AUTOSAR XML (schema 4-0-3)
package /ComponentTypes
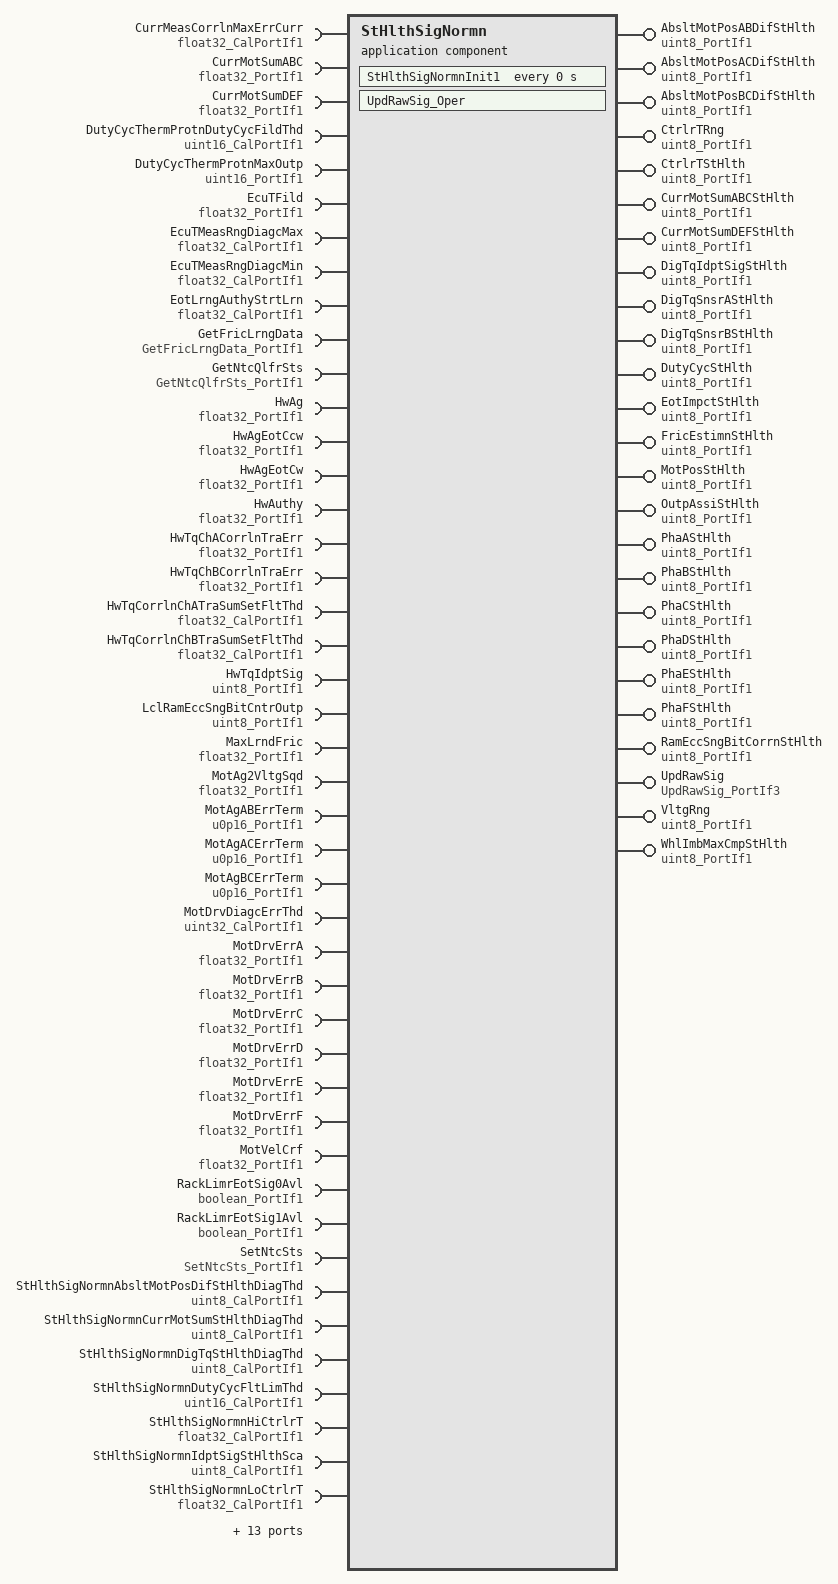
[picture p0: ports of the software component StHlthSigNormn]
  application sw component type StHlthSigNormn
    25 x provide port:
      AbsltMotPosABDifStHlth: nonqueued-sender-com-spec{data-element=Val, init-value=100}, provided-interface=uint8_PortIf1
      AbsltMotPosACDifStHlth: nonqueued-sender-com-spec{data-element=Val, init-value=100}, provided-interface=uint8_PortIf1
      AbsltMotPosBCDifStHlth: nonqueued-sender-com-spec{data-element=Val, init-value=100}, provided-interface=uint8_PortIf1
      CtrlrTRng: nonqueued-sender-com-spec{data-element=Val, init-value=0}, provided-interface=uint8_PortIf1
      CtrlrTStHlth: nonqueued-sender-com-spec{data-element=Val, init-value=100}, provided-interface=uint8_PortIf1
      CurrMotSumABCStHlth: nonqueued-sender-com-spec{data-element=Val, init-value=100}, provided-interface=uint8_PortIf1
      CurrMotSumDEFStHlth: nonqueued-sender-com-spec{data-element=Val, init-value=100}, provided-interface=uint8_PortIf1
      DigTqIdptSigStHlth: nonqueued-sender-com-spec{data-element=Val, init-value=100}, provided-interface=uint8_PortIf1
      DigTqSnsrAStHlth: nonqueued-sender-com-spec{data-element=Val, init-value=100}, provided-interface=uint8_PortIf1
      DigTqSnsrBStHlth: nonqueued-sender-com-spec{data-element=Val, init-value=100}, provided-interface=uint8_PortIf1
      DutyCycStHlth: nonqueued-sender-com-spec{data-element=Val, init-value=100}, provided-interface=uint8_PortIf1
      EotImpctStHlth: nonqueued-sender-com-spec{data-element=Val, init-value=100}, provided-interface=uint8_PortIf1
      FricEstimnStHlth: nonqueued-sender-com-spec{data-element=Val, init-value=100}, provided-interface=uint8_PortIf1
      MotPosStHlth: nonqueued-sender-com-spec{data-element=Val, init-value=100}, provided-interface=uint8_PortIf1
      OutpAssiStHlth: nonqueued-sender-com-spec{data-element=Val, init-value=100}, provided-interface=uint8_PortIf1
      PhaAStHlth: nonqueued-sender-com-spec{data-element=Val, init-value=100}, provided-interface=uint8_PortIf1
      PhaBStHlth: nonqueued-sender-com-spec{data-element=Val, init-value=100}, provided-interface=uint8_PortIf1
      PhaCStHlth: nonqueued-sender-com-spec{data-element=Val, init-value=100}, provided-interface=uint8_PortIf1
      PhaDStHlth: nonqueued-sender-com-spec{data-element=Val, init-value=100}, provided-interface=uint8_PortIf1
      PhaEStHlth: nonqueued-sender-com-spec{data-element=Val, init-value=100}, provided-interface=uint8_PortIf1
      PhaFStHlth: nonqueued-sender-com-spec{data-element=Val, init-value=100}, provided-interface=uint8_PortIf1
      RamEccSngBitCorrnStHlth: nonqueued-sender-com-spec{data-element=Val, init-value=100}, provided-interface=uint8_PortIf1
      UpdRawSig: server-com-spec{operation=Oper, queue-length=1}, provided-interface=UpdRawSig_PortIf3
      VltgRng: nonqueued-sender-com-spec{data-element=Val, init-value=0}, provided-interface=uint8_PortIf1
      WhlImbMaxCmpStHlth: nonqueued-sender-com-spec{data-element=Val, init-value=100}, provided-interface=uint8_PortIf1
    57 x require port:
      CurrMeasCorrlnMaxErrCurr: parameter-require-com-spec{init-value=12.0, parameter=Val}, required-interface=float32_CalPortIf1
      CurrMotSumABC: nonqueued-receiver-com-spec{data-element=Val, filter=data-filter-type=ALWAYS, init-value=0.0}, required-interface=float32_PortIf1
      CurrMotSumDEF: nonqueued-receiver-com-spec{data-element=Val, filter=data-filter-type=ALWAYS, init-value=0.0}, required-interface=float32_PortIf1
      DutyCycThermProtnDutyCycFildThd: parameter-require-com-spec{init-value=92, parameter=Val}, required-interface=uint16_CalPortIf1
      DutyCycThermProtnMaxOutp: nonqueued-receiver-com-spec{data-element=Val, filter=data-filter-type=ALWAYS, init-value=0}, required-interface=uint16_PortIf1
      EcuTFild: nonqueued-receiver-com-spec{data-element=Val, filter=data-filter-type=ALWAYS, init-value=0}, required-interface=float32_PortIf1
      EcuTMeasRngDiagcMax: parameter-require-com-spec{init-value=145.0, parameter=Val}, required-interface=float32_CalPortIf1
      EcuTMeasRngDiagcMin: parameter-require-com-spec{init-value=-45.0, parameter=Val}, required-interface=float32_CalPortIf1
      EotLrngAuthyStrtLrn: parameter-require-com-spec{init-value=1.0, parameter=Val}, required-interface=float32_CalPortIf1
      GetFricLrngData: required-interface=GetFricLrngData_PortIf1
      GetNtcQlfrSts: required-interface=GetNtcQlfrSts_PortIf1
      HwAg: nonqueued-receiver-com-spec{data-element=Val, filter=data-filter-type=ALWAYS, init-value=0}, required-interface=float32_PortIf1
      HwAgEotCcw: nonqueued-receiver-com-spec{data-element=Val, filter=data-filter-type=ALWAYS, init-value=-360.0}, required-interface=float32_PortIf1
      HwAgEotCw: nonqueued-receiver-com-spec{data-element=Val, filter=data-filter-type=ALWAYS, init-value=360.0}, required-interface=float32_PortIf1
      HwAuthy: nonqueued-receiver-com-spec{data-element=Val, filter=data-filter-type=ALWAYS, init-value=0}, required-interface=float32_PortIf1
      HwTqChACorrlnTraErr: nonqueued-receiver-com-spec{data-element=Val, filter=data-filter-type=ALWAYS, init-value=0}, required-interface=float32_PortIf1
      HwTqChBCorrlnTraErr: nonqueued-receiver-com-spec{data-element=Val, filter=data-filter-type=ALWAYS, init-value=0}, required-interface=float32_PortIf1
      HwTqCorrlnChATraSumSetFltThd: parameter-require-com-spec{init-value=2.85, parameter=Val}, required-interface=float32_CalPortIf1
      HwTqCorrlnChBTraSumSetFltThd: parameter-require-com-spec{init-value=2.85, parameter=Val}, required-interface=float32_CalPortIf1
      HwTqIdptSig: nonqueued-receiver-com-spec{data-element=Val, filter=data-filter-type=ALWAYS, init-value=4}, required-interface=uint8_PortIf1
      LclRamEccSngBitCntrOutp: nonqueued-receiver-com-spec{data-element=Val, filter=data-filter-type=ALWAYS, init-value=0}, required-interface=uint8_PortIf1
      MaxLrndFric: nonqueued-receiver-com-spec{data-element=Val, filter=data-filter-type=ALWAYS, init-value=0}, required-interface=float32_PortIf1
      MotAg2VltgSqd: nonqueued-receiver-com-spec{data-element=Val, filter=data-filter-type=ALWAYS, init-value=1.755625}, required-interface=float32_PortIf1
      MotAgABErrTerm: nonqueued-receiver-com-spec{data-element=Val, filter=data-filter-type=ALWAYS, init-value=0}, required-interface=u0p16_PortIf1
      MotAgACErrTerm: nonqueued-receiver-com-spec{data-element=Val, filter=data-filter-type=ALWAYS, init-value=0}, required-interface=u0p16_PortIf1
      MotAgBCErrTerm: nonqueued-receiver-com-spec{data-element=Val, filter=data-filter-type=ALWAYS, init-value=0}, required-interface=u0p16_PortIf1
      MotDrvDiagcErrThd: parameter-require-com-spec{init-value=180000, parameter=Val}, required-interface=uint32_CalPortIf1
      MotDrvErrA: nonqueued-receiver-com-spec{data-element=Val, filter=data-filter-type=ALWAYS, init-value=0}, required-interface=float32_PortIf1
      MotDrvErrB: nonqueued-receiver-com-spec{data-element=Val, filter=data-filter-type=ALWAYS, init-value=0}, required-interface=float32_PortIf1
      MotDrvErrC: nonqueued-receiver-com-spec{data-element=Val, filter=data-filter-type=ALWAYS, init-value=0}, required-interface=float32_PortIf1
      MotDrvErrD: nonqueued-receiver-com-spec{data-element=Val, filter=data-filter-type=ALWAYS, init-value=0}, required-interface=float32_PortIf1
      MotDrvErrE: nonqueued-receiver-com-spec{data-element=Val, filter=data-filter-type=ALWAYS, init-value=0}, required-interface=float32_PortIf1
      MotDrvErrF: nonqueued-receiver-com-spec{data-element=Val, filter=data-filter-type=ALWAYS, init-value=0}, required-interface=float32_PortIf1
      MotVelCrf: nonqueued-receiver-com-spec{data-element=Val, filter=data-filter-type=ALWAYS, init-value=0}, required-interface=float32_PortIf1
      RackLimrEotSig0Avl: nonqueued-receiver-com-spec{data-element=Logl, filter=data-filter-type=ALWAYS, init-value=0}, required-interface=boolean_PortIf1
      RackLimrEotSig1Avl: nonqueued-receiver-com-spec{data-element=Logl, filter=data-filter-type=ALWAYS, init-value=0}, required-interface=boolean_PortIf1
      SetNtcSts: required-interface=SetNtcSts_PortIf1
      StHlthSigNormnAbsltMotPosDifStHlthDiagThd: parameter-require-com-spec{init-value=67, parameter=Val}, required-interface=uint8_CalPortIf1
      StHlthSigNormnCurrMotSumStHlthDiagThd: parameter-require-com-spec{init-value=67, parameter=Val}, required-interface=uint8_CalPortIf1
      StHlthSigNormnDigTqStHlthDiagThd: parameter-require-com-spec{init-value=67, parameter=Val}, required-interface=uint8_CalPortIf1
      StHlthSigNormnDutyCycFltLimThd: parameter-require-com-spec{init-value=84, parameter=Val}, required-interface=uint16_CalPortIf1
      StHlthSigNormnHiCtrlrT: parameter-require-com-spec{init-value=140.0, parameter=Val}, required-interface=float32_CalPortIf1
      StHlthSigNormnIdptSigStHlthSca: parameter-require-com-spec{init-value=22, parameter=Val}, required-interface=uint8_CalPortIf1
      StHlthSigNormnLoCtrlrT: parameter-require-com-spec{init-value=-40.0, parameter=Val}, required-interface=float32_CalPortIf1
      StHlthSigNormnMaxFricThd: parameter-require-com-spec{init-value=15, parameter=Val}, required-interface=float32_CalPortIf1
      StHlthSigNormnMinRackTrvlLim: parameter-require-com-spec{init-value=5.0, parameter=Val}, required-interface=float32_CalPortIf1
      StHlthSigNormnMotPosStHlthDiagThd: parameter-require-com-spec{init-value=67, parameter=Val}, required-interface=uint8_CalPortIf1
      StHlthSigNormnMotVelCal: parameter-require-com-spec{init-value=20.0, parameter=Val}, required-interface=float32_CalPortIf1
      StHlthSigNormnPhaInfoStHlthDiagThd: parameter-require-com-spec{init-value=67, parameter=Val}, required-interface=uint8_CalPortIf1
      StHlthSigNormnStHlthCorrlnErr: parameter-require-com-spec{init-value=0, parameter=Val}, required-interface=u0p16_CalPortIf1
      StHlthSigNormnStHlthCurrMotSum: parameter-require-com-spec{init-value=0.0, parameter=Val}, required-interface=float32_CalPortIf1
      StHlthSigNormnStHlthPhaInfo: parameter-require-com-spec{init-value=0, parameter=Val}, required-interface=float32_CalPortIf1
      StHlthSigNormnValMaxStHlthErr: parameter-require-com-spec{init-value=3.48, parameter=Val}, required-interface=float32_CalPortIf1
      StHlthSigNormnValMinStHlthErr: parameter-require-com-spec{init-value=0.62, parameter=Val}, required-interface=float32_CalPortIf1
      StHlthSigNormnWhlImbRejctnThd: parameter-require-com-spec{init-value=5, parameter=Val}, required-interface=float32_CalPortIf1
      SysGlbPrmMotPoleCnt: parameter-require-com-spec{init-value=6, parameter=Val}, required-interface=uint8_CalPortIf1
      WhlImbRejctnCmd: nonqueued-receiver-com-spec{data-element=Val, filter=data-filter-type=ALWAYS, init-value=0}, required-interface=float32_PortIf1
    behavior StHlthSigNormn_InternalBehavior
      ar-typed-per-instance-memorys:
        20 x data, all with sw-calibration-access=READ-ONLY:
          AbsltMotPosABDifStHlthSts: type=uint8
          AbsltMotPosACDifStHlthSts: type=uint8
          AbsltMotPosBCDifStHlthSts: type=uint8
          CurrMotSumABCStHlthSts: type=uint8
          CurrMotSumDEFStHlthSts: type=uint8
          DigTqIdptSigStHlthSts: type=uint8
          DigTqSnsrAStHlthSts: type=uint8
          DigTqSnsrBStHlthSts: type=uint8
          EcuTRngIgnCyc: type=uint8
          EntrEot: type=boolean
          EotImpctCntr: type=uint8
          MotAgCorrlnErrThd: type=u0p16
          MotPosStHlthSts: type=uint8
          PhaAStHlthSts: type=uint8
          PhaBStHlthSts: type=uint8
          PhaCStHlthSts: type=uint8
          PhaDStHlthSts: type=uint8
          PhaEStHlthSts: type=uint8
          PhaFStHlthSts: type=uint8
          VltgRngIgnCyc: type=uint8
      timing event StHlthSigNormn_InitEvent: start-on-event=StHlthSigNormnInit1, period=0
      operation invoked event OIT_UpdRawSig_Oper_UpdRawSig_Oper: start-on-event=UpdRawSig_Oper, operation=UpdRawSig.Oper
      explicit-inter-runnable-variables:
        data EolFric: type=float32, init-value=0
      runnable StHlthSigNormnInit1
        data-send-points:
          22 x access:
            SEND_AbsltMotPosABDifStHlth_Val: accessed-variable=AbsltMotPosABDifStHlth.Val
            SEND_AbsltMotPosACDifStHlth_Val: accessed-variable=AbsltMotPosACDifStHlth.Val
            SEND_AbsltMotPosBCDifStHlth_Val: accessed-variable=AbsltMotPosBCDifStHlth.Val
            SEND_CtrlrTStHlth_Val: accessed-variable=CtrlrTStHlth.Val
            SEND_CtrlTRng_Val: accessed-variable=CtrlrTRng.Val
            SEND_CurrMotSumABCStHlth_Val: accessed-variable=CurrMotSumABCStHlth.Val
            SEND_CurrMotSumDEFStHlth_Val: accessed-variable=CurrMotSumDEFStHlth.Val
            SEND_DigTqIdptSigStHlth_Val: accessed-variable=DigTqIdptSigStHlth.Val
            SEND_DigTqSnsrAStHlth_Val: accessed-variable=DigTqSnsrAStHlth.Val
            SEND_DigTqSnsrBStHlth_Val: accessed-variable=DigTqSnsrBStHlth.Val
            SEND_DutyCycStHlth_Val: accessed-variable=DutyCycStHlth.Val
            SEND_EotImpctStHlth_Val: accessed-variable=EotImpctStHlth.Val
            SEND_MotPosStHlth_Val: accessed-variable=MotPosStHlth.Val
            SEND_OutpAssiStHlth_Val: accessed-variable=OutpAssiStHlth.Val
            SEND_PhaAStHlth_Val: accessed-variable=PhaAStHlth.Val
            SEND_PhaBStHlth_Val: accessed-variable=PhaBStHlth.Val
            SEND_PhaCStHlth_Val: accessed-variable=PhaCStHlth.Val
            SEND_PhaDStHlth_Val: accessed-variable=PhaDStHlth.Val
            SEND_PhaEStHlth_Val: accessed-variable=PhaEStHlth.Val
            SEND_PhaFStHlth_Val: accessed-variable=PhaFStHlth.Val
            SEND_RamEccSngBitCorrnStHlth_Val: accessed-variable=RamEccSngBitCorrnStHlth.Val
            SEND_VltgRng_Val: accessed-variable=VltgRng.Val
        sync call SC_GetFricLrngData_Oper: operation=GetFricLrngData.Oper, timeout=0
        written-local-variables:
          access WRITE_EolFric: accessed-variable=EolFric
      runnable UpdRawSig_Oper: can-be-invoked-concurrently=true
        data-receive-point-by-arguments:
          27 x access:
            REC_CurrMotSumABC_Val: accessed-variable=CurrMotSumABC.Val
            REC_CurrMotSumDEF_Val: accessed-variable=CurrMotSumDEF.Val
            REC_DutyCycThermProtnMaxOutp_Val: accessed-variable=DutyCycThermProtnMaxOutp.Val
            REC_EcuTFild_Val: accessed-variable=EcuTFild.Val
            REC_HwAg_Val: accessed-variable=HwAg.Val
            REC_HwAgEotCcw_Val: accessed-variable=HwAgEotCcw.Val
            REC_HwAgEotCw_Val: accessed-variable=HwAgEotCw.Val
            REC_HwAuthy_Val: accessed-variable=HwAuthy.Val
            REC_HwTqChACorrlnTraErr_Val: accessed-variable=HwTqChACorrlnTraErr.Val
            REC_HwTqChBCorrlnTraErr_Val: accessed-variable=HwTqChBCorrlnTraErr.Val
            REC_HwTqIdptSig_Val: accessed-variable=HwTqIdptSig.Val
            REC_LclRamEccSngBitCntrOutp_Val: accessed-variable=LclRamEccSngBitCntrOutp.Val
            REC_MaxLrndFric_Val: accessed-variable=MaxLrndFric.Val
            REC_MotAgABErrTerm_Val_1: accessed-variable=MotAgABErrTerm.Val
            REC_MotAgACErrTerm_Val_1: accessed-variable=MotAgACErrTerm.Val
            REC_MotAgBCErrTerm_Val_1: accessed-variable=MotAgBCErrTerm.Val
            REC_MotDrvErrA_Val: accessed-variable=MotDrvErrA.Val
            REC_MotDrvErrB_Val: accessed-variable=MotDrvErrB.Val
            REC_MotDrvErrC_Val: accessed-variable=MotDrvErrC.Val
            REC_MotDrvErrD_Val: accessed-variable=MotDrvErrD.Val
            REC_MotDrvErrE_Val: accessed-variable=MotDrvErrE.Val
            REC_MotDrvErrF_Val: accessed-variable=MotDrvErrF.Val
            REC_MotVelCrf_Val: accessed-variable=MotVelCrf.Val
            REC_RackLimrEotSig0Avl_Logl: accessed-variable=RackLimrEotSig0Avl.Logl
            REC_RackLimrEotSig1Avl_Logl: accessed-variable=RackLimrEotSig1Avl.Logl
            REC_VltgSqd_Val: accessed-variable=MotAg2VltgSqd.Val
            REC_WhlImbRejctnCmd_Val: accessed-variable=WhlImbRejctnCmd.Val
        data-send-points:
          24 x access:
            SEND_AbsltMotPosABDifStHlth_Val: accessed-variable=AbsltMotPosABDifStHlth.Val
            SEND_AbsltMotPosACDifStHlth_Val: accessed-variable=AbsltMotPosACDifStHlth.Val
            SEND_AbsltMotPosBCDifStHlth_Val: accessed-variable=AbsltMotPosBCDifStHlth.Val
            SEND_CtrlrTStHlth_Val: accessed-variable=CtrlrTStHlth.Val
            SEND_CtrlTRng_Val: accessed-variable=CtrlrTRng.Val
            SEND_CurrMotSumABCStHlth_Val: accessed-variable=CurrMotSumABCStHlth.Val
            SEND_CurrMotSumDEFStHlth_Val: accessed-variable=CurrMotSumDEFStHlth.Val
            SEND_DigTqIdptSigStHlth_Val: accessed-variable=DigTqIdptSigStHlth.Val
            SEND_DigTqSnsrAStHlth_Val: accessed-variable=DigTqSnsrAStHlth.Val
            SEND_DigTqSnsrBStHlth_Val: accessed-variable=DigTqSnsrBStHlth.Val
            SEND_DutyCycStHlth_Val: accessed-variable=DutyCycStHlth.Val
            SEND_EotImpctStHlth_Val: accessed-variable=EotImpctStHlth.Val
            SEND_FricEstimnStHlth_Val: accessed-variable=FricEstimnStHlth.Val
            SEND_MotPosStHlth_Val: accessed-variable=MotPosStHlth.Val
            SEND_OutpAssiStHlth_Val: accessed-variable=OutpAssiStHlth.Val
            SEND_PhaAStHlth_Val: accessed-variable=PhaAStHlth.Val
            SEND_PhaBStHlth_Val: accessed-variable=PhaBStHlth.Val
            SEND_PhaCStHlth_Val: accessed-variable=PhaCStHlth.Val
            SEND_PhaDStHlth_Val: accessed-variable=PhaDStHlth.Val
            SEND_PhaEStHlth_Val: accessed-variable=PhaEStHlth.Val
            SEND_PhaFStHlth_Val: accessed-variable=PhaFStHlth.Val
            SEND_RamEccSngBitCorrnStHlth_Val: accessed-variable=RamEccSngBitCorrnStHlth.Val
            SEND_VltgRng_Val: accessed-variable=VltgRng.Val
            SEND_WhlImbMaxCmpStHlth_Val: accessed-variable=WhlImbMaxCmpStHlth.Val
        read-local-variables:
          access READ_EolFric: accessed-variable=EolFric
        sync call SC_GetNtcQlfrSts_Oper: operation=GetNtcQlfrSts.Oper, timeout=0
        sync call SC_SetNtcSts_Oper: operation=SetNtcSts.Oper, timeout=0
  swc implementation StHlthSigNormn_Implementation: behavior=StHlthSigNormn_InternalBehavior
    code-descriptors:
      code Default: artifact-descriptors=autosar-engineering-object={short-label=Default, category=SWSRC}
